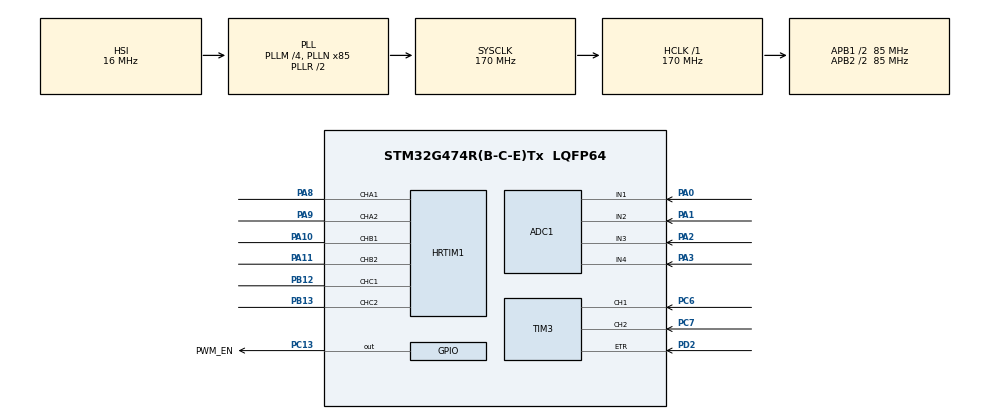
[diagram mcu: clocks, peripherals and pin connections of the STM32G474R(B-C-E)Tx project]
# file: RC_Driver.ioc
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ADC1.Channel-0\#ChannelRegularConversion=ADC_CHANNEL_1
ADC1.EnableInjectedConversion=ENABLE
ADC1.ExternalTrigInjecConv=ADC_EXTERNALTRIGINJEC_HRTIM_TRG2
ADC1.InjNumberOfConversion=4
ADC1.InjectedChannel-1\#ChannelInjectedConversion=ADC_CHANNEL_1
ADC1.InjectedChannel-2\#ChannelInjectedConversion=ADC_CHANNEL_2
ADC1.InjectedChannel-3\#ChannelInjectedConversion=ADC_CHANNEL_3
ADC1.InjectedChannel-4\#ChannelInjectedConversion=ADC_CHANNEL_4
ADC1.InjectedOffsetNumber-1\#ChannelInjectedConversion=ADC_OFFSET_NONE
ADC1.InjectedOffsetNumber-2\#ChannelInjectedConversion=ADC_OFFSET_NONE
ADC1.InjectedOffsetNumber-3\#ChannelInjectedConversion=ADC_OFFSET_NONE
ADC1.InjectedOffsetNumber-4\#ChannelInjectedConversion=ADC_OFFSET_NONE
ADC1.InjectedRank-1\#ChannelInjectedConversion=1
ADC1.InjectedRank-2\#ChannelInjectedConversion=2
ADC1.InjectedRank-3\#ChannelInjectedConversion=3
ADC1.InjectedRank-4\#ChannelInjectedConversion=4
ADC1.InjectedSamplingTime-1\#ChannelInjectedConversion=ADC_SAMPLETIME_2CYCLES_5
ADC1.InjectedSamplingTime-2\#ChannelInjectedConversion=ADC_SAMPLETIME_2CYCLES_5
ADC1.InjectedSamplingTime-3\#ChannelInjectedConversion=ADC_SAMPLETIME_2CYCLES_5
ADC1.InjectedSamplingTime-4\#ChannelInjectedConversion=ADC_SAMPLETIME_47CYCLES_5
ADC1.NbrOfConversion=1
ADC1.NbrOfConversionFlag=1
ADC1.OffsetNumber-0\#ChannelRegularConversion=ADC_OFFSET_NONE
ADC1.Rank-0\#ChannelRegularConversion=1
ADC1.Rank1_Channel=ADC_CHANNEL_1
ADC1.Rank2_Channel=ADC_CHANNEL_2
ADC1.Rank3_Channel=ADC_CHANNEL_3
ADC1.Rank4_Channel=ADC_CHANNEL_4
ADC1.SamplingTime-0\#ChannelRegularConversion=ADC_SAMPLETIME_2CYCLES_5
ADC1.master=1
HRTIM1.ADCTrigger2_Source1=HRTIM_ADCTRIGGEREVENT24_TIMERA_PERIOD
HRTIM1.ADCTrigger_Id1=__NULL
HRTIM1.ADCTrigger_Id2=HRTIM_ADCTRIGGER_2
HRTIM1.Adrom_TA=HRTIM_TIM_ADROM_BOTH
HRTIM1.CompareUnit1-MasterTimer=__NULL
HRTIM1.CompareUnit1-Output_TA1TA2=HRTIM_COMPAREUNIT_1
HRTIM1.CompareUnit1-Output_TB1TB2=HRTIM_COMPAREUNIT_1
HRTIM1.CompareUnit1-Output_TC1TC2=HRTIM_COMPAREUNIT_1
HRTIM1.CompareValue1-Output_TA1TA2=0
HRTIM1.CompareValue1-Output_TB1TB2=0
HRTIM1.CompareValue1-Output_TC1TC2=0
HRTIM1.DeadTimeInsertion-Output_TA1TA2=HRTIM_TIMDEADTIMEINSERTION_ENABLED
HRTIM1.DeadTimeInsertion-Output_TB1TB2=HRTIM_TIMDEADTIMEINSERTION_ENABLED
HRTIM1.DeadTimeInsertion-Output_TC1TC2=HRTIM_TIMDEADTIMEINSERTION_ENABLED
HRTIM1.FallingValue-Output_TA1TA2=35
HRTIM1.FallingValue-Output_TB1TB2=35
HRTIM1.FallingValue-Output_TC1TC2=35
HRTIM1.FaultEnable_Source1-Output_TA1TA2=HRTIM_TIMFAULTENABLE_FAULT3
HRTIM1.FaultEnable_Source1-Output_TB1TB2=HRTIM_TIMFAULTENABLE_FAULT3
HRTIM1.FaultEnable_Source1-Output_TC1TC2=HRTIM_TIMFAULTENABLE_FAULT3
HRTIM1.FaultLevel1-Output_TA1TA2=HRTIM_OUTPUTFAULTLEVEL_INACTIVE
HRTIM1.FaultLevel1-Output_TB1TB2=HRTIM_OUTPUTFAULTLEVEL_INACTIVE
HRTIM1.FaultLevel1-Output_TC1TC2=HRTIM_OUTPUTFAULTLEVEL_INACTIVE
HRTIM1.FaultLevel2-Output_TA1TA2=HRTIM_OUTPUTFAULTLEVEL_INACTIVE
HRTIM1.FaultLevel2-Output_TB1TB2=HRTIM_OUTPUTFAULTLEVEL_INACTIVE
HRTIM1.FaultLevel2-Output_TC1TC2=HRTIM_OUTPUTFAULTLEVEL_INACTIVE
HRTIM1.FaultLock-Output_TA1TA2=HRTIM_TIMFAULTLOCK_READWRITE
HRTIM1.Fault_Line1=__NULL
HRTIM1.Fault_Line3=HRTIM_FAULT_3
HRTIM1.Filter_FaultLine3=HRTIM_FAULTFILTER_6
HRTIM1.HRTIMInterruptResquests1=HRTIM_IT_NONE
HRTIM1.NumberADCTriggerSource2=1
HRTIM1.NumberFaultEnable-Output_TA1TA2=1
HRTIM1.NumberFaultEnable-Output_TB1TB2=1
HRTIM1.NumberFaultEnable-Output_TC1TC2=1
HRTIM1.NumberResetSource1-Output_TA1TA2=1
HRTIM1.NumberResetSource1-Output_TB1TB2=1
HRTIM1.NumberResetSource1-Output_TC1TC2=1
HRTIM1.NumberResetSource2_TA=0
HRTIM1.NumberResetSource2_TB=0
HRTIM1.NumberResetSource2_TC=0
HRTIM1.NumberSetSource1-Output_TA1TA2=1
HRTIM1.NumberSetSource1-Output_TB1TB2=1
HRTIM1.NumberSetSource1-Output_TC1TC2=1
HRTIM1.NumberSetSource2_TA=0
HRTIM1.NumberSetSource2_TB=0
HRTIM1.NumberSetSource2_TC=0
HRTIM1.Periode_MASTER=8500
HRTIM1.Periode_TA=4250
HRTIM1.Periode_TB=4250
HRTIM1.Periode_TC=4250
HRTIM1.Polarity2-Output_TA1TA2=HRTIM_OUTPUTPOLARITY_HIGH
HRTIM1.Polarity_FaultLine3=HRTIM_FAULTPOLARITY_LOW
HRTIM1.PreloadEnable-Output_TA1TA2=HRTIM_PRELOAD_ENABLED
HRTIM1.PreloadEnable-Output_TB1TB2=HRTIM_PRELOAD_ENABLED
HRTIM1.PreloadEnable-Output_TC1TC2=HRTIM_PRELOAD_ENABLED
HRTIM1.PrescalerDead-Output_TA1TA2=HRTIM_TIMDEADTIME_PRESCALERRATIO_DIV1
HRTIM1.PrescalerDead-Output_TB1TB2=HRTIM_TIMDEADTIME_PRESCALERRATIO_DIV1
HRTIM1.PrescalerDead-Output_TC1TC2=HRTIM_TIMDEADTIME_PRESCALERRATIO_DIV1
HRTIM1.PrescalerRatio_MASTER=HRTIM_PRESCALERRATIO_DIV1
HRTIM1.PrescalerRatio_TA=HRTIM_PRESCALERRATIO_DIV1
HRTIM1.PrescalerRatio_TB=HRTIM_PRESCALERRATIO_DIV1
HRTIM1.PrescalerRatio_TC=HRTIM_PRESCALERRATIO_DIV1
HRTIM1.RepetitionCounter-MasterTimer=0x01
HRTIM1.RepetitionCounter-Output_TA1TA2=0x01
HRTIM1.RepetitionCounter-Output_TB1TB2=0x01
HRTIM1.RepetitionCounter-Output_TC1TC2=0x1
HRTIM1.ResetOutput1_Source1-Output_TA1TA2=HRTIM_OUTPUTRESET_TIMCMP1
HRTIM1.ResetOutput1_Source1-Output_TB1TB2=HRTIM_OUTPUTRESET_TIMCMP1
HRTIM1.ResetOutput1_Source1-Output_TC1TC2=HRTIM_OUTPUTRESET_TIMCMP1
HRTIM1.RisingValue-Output_TA1TA2=35
HRTIM1.RisingValue-Output_TB1TB2=35
HRTIM1.RisingValue-Output_TC1TC2=35
HRTIM1.SetOutput1_Source1-Output_TA1TA2=HRTIM_OUTPUTSET_TIMPER
HRTIM1.SetOutput1_Source1-Output_TB1TB2=HRTIM_OUTPUTSET_TIMPER
HRTIM1.SetOutput1_Source1-Output_TC1TC2=HRTIM_OUTPUTSET_TIMPER
HRTIM1.UpDownMode-Output_TA1TA2=HRTIM_TIMERUPDOWNMODE_UPDOWN
HRTIM1.UpDownMode-Output_TB1TB2=HRTIM_TIMERUPDOWNMODE_UPDOWN
HRTIM1.UpDownMode-Output_TC1TC2=HRTIM_TIMERUPDOWNMODE_UPDOWN
Mcu.Family=STM32G4
Mcu.Name=STM32G474R(B-C-E)Tx
Mcu.Package=LQFP64
NVIC.ADC1_2_IRQn=true\:0\:0\:false\:false\:true\:true\:true\:true
NVIC.HRTIM1_FLT_IRQn=true\:0\:0\:false\:false\:true\:true\:true\:true
NVIC.PriorityGroup=NVIC_PRIORITYGROUP_4
NVIC.TIM2_IRQn=true\:0\:0\:false\:false\:true\:true\:true\:true
PA0.Mode=IN1-Single-Ended
PA0.Signal=ADC1_IN1
PA1.Mode=IN2-Single-Ended
PA1.Signal=ADC1_IN2
PA10.Mode=Output_TB1TB2
PA10.Signal=HRTIM1_CHB1
PA11.Mode=Output_TB1TB2
PA11.Signal=HRTIM1_CHB2
PA13.Mode=Serial_Wire
PA13.Signal=SYS_JTMS-SWDIO
PA14.Mode=Serial_Wire
PA14.Signal=SYS_JTCK-SWCLK
PA2.Mode=IN3-Single-Ended
PA2.Signal=ADC1_IN3
PA3.Mode=IN4-Single-Ended
PA3.Signal=ADC1_IN4
PA8.Mode=Output_TA1TA2
PA8.Signal=HRTIM1_CHA1
PA9.Mode=Output_TA1TA2
PA9.Signal=HRTIM1_CHA2
PB12.Mode=Output_TC1TC2
PB12.Signal=HRTIM1_CHC1
PB13.Mode=Output_TC1TC2
PB13.Signal=HRTIM1_CHC2
PC13.GPIO_Label=PWM_EN
PC13.Signal=GPIO_Output
PC6.Signal=S_TIM3_CH1
PC7.Signal=S_TIM3_CH2
PD2.Signal=S_TIM3_ETR
ProjectManager.HeapSize=0x200
ProjectManager.StackSize=0x400
ProjectManager.TargetToolchain=STM32CubeIDE
RCC.ADC12Freq_Value=170000000
RCC.ADC345Freq_Value=170000000
RCC.AHBFreq_Value=170000000
RCC.APB1CLKDivider=RCC_HCLK_DIV2
RCC.APB1Freq_Value=85000000
RCC.APB1TimFreq_Value=170000000
RCC.APB2CLKDivider=RCC_HCLK_DIV2
RCC.APB2Freq_Value=85000000
RCC.APB2TimFreq_Value=170000000
RCC.CortexFreq_Value=170000000
RCC.EXTERNAL_CLOCK_VALUE=12288000
RCC.HCLKFreq_Value=170000000
RCC.HSE_VALUE=8000000
RCC.HSI48_VALUE=48000000
RCC.HSI_VALUE=16000000
RCC.LSE_VALUE=32768
RCC.PLLM=RCC_PLLM_DIV4
RCC.PLLN=85
RCC.SYSCLKFreq_VALUE=170000000
RCC.SYSCLKSource=RCC_SYSCLKSOURCE_PLLCLK
RCC.USBFreq_Value=170000000
RCC.VCOOutputFreq_Value=340000000
SH.S_TIM3_CH1.0=TIM3_CH1,Encoder_Interface_w_index
SH.S_TIM3_CH2.0=TIM3_CH2,Encoder_Interface_w_index
SH.S_TIM3_ETR.0=TIM3_ETR,Encoder_Interface_w_index
TIM2.Channel-Output\ Compare2\ No\ Output=TIM_CHANNEL_2
TIM2.PeriodNoDither=17000-1
TIM2.PulseNoDither_2=2100
TIM2.TIM_MasterOutputTrigger=TIM_TRGO_OC1
TIM2.TIM_MasterSlaveMode=TIM_MASTERSLAVEMODE_ENABLE
VP_HRTIM1_VS_hrtimMasterTimerNoOutput.Mode=MasterTimer
VP_SYS_VS_DBSignals.Mode=DisableDeadBatterySignals
VP_TIM2_VS_ClockSourceINT.Mode=Internal
VP_TIM2_VS_no_output2.Mode=Output Compare2 No Output
board=custom

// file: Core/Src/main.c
/* USER CODE BEGIN Header */
/**
  ******************************************************************************
  * @file           : main.c
  * @brief          : Main program body
  ******************************************************************************
  * @attention
  *
  * Copyright (c) 2026 STMicroelectronics.
  * All rights reserved.
  *
  * This software is licensed under terms that can be found in the LICENSE file
  * in the root directory of this software component.
  * If no LICENSE file comes with this software, it is provided AS-IS.
  *
  ******************************************************************************
  */
/* USER CODE END Header */
#include "main.h"
#include "adc.h"
#include "hrtim.h"
#include "tim.h"
#include "gpio.h"

/* USER CODE BEGIN PV */
float dutyCycle = 0.0f;
/* USER CODE END PV */

void SystemClock_Config(void);

int main(void)
{

  /* MCU Configuration--------------------------------------------------------*/

  /* Reset of all peripherals, Initializes the Flash interface and the Systick. */
  HAL_Init();

  /* Configure the system clock */
  SystemClock_Config();

  /* Initialize all configured peripherals */
  MX_GPIO_Init();
  MX_HRTIM1_Init();
  MX_ADC1_Init();
  MX_TIM3_Init();
  MX_TIM2_Init();
  /* USER CODE BEGIN 2 */

  //  InitParameter(&INV,
  //  			//		SPM
  //  			0.2034f,		// Rs
  //  			2.941e-3,	// Ld
  //  			2.941e-3,	// Lq
  //  			0.07796f,	// Lamf
  //  			4.f,		// PP
  //  			0.748e-3,	// Jm
  //  			1.e-4,	// Bm
  //  			1.f,		// Idsr_align
  //  			4.5f,		// Is_rated  // 12.445
  //  			3.0f,		// Is_limit
  //  			3000.f,	// Wrpm_rated
  //  			0.776f	// Te_rated
  //  );

    //InitParameter(&INV, 5.87e-3, 0.61e-6, 0.61e-6, 728e-6, 4.f, 1e-6, 1e-6, 2.f, 10.f, 20.f, 35000.f, 1e-2); // Velineon 3500
    InitParameter(&INV, 19e-3, 3.2e-6, 3.2e-6, 2e-3, 1.f, 1e-6, 1e-6, 2.f, 50.f, 50.f, 10000.f, 3); // XERUN 13.5T
  //  InitParameter(&INV, 7.85e-3, 0.35e-6, 0.35e-6, 0.711e-3, 4.f, 1e-6, 1e-6, 2.f, 40.f, 40.f, 10000.f, 3); // CASTLE 13.5T

    InitSpeedController(&INV, PI2*25.f, 0.707f);		//PI2*2.	0.707
  //  InitFluxWeakeningController(&INV, 0.0001f, 1.f);
  //  InitTorqueController(&INV);
    InitCurrentController(&INV, PI2*1000.f);	//PI2*200.

    Init_Spd_PLL(&INV, PI2*20.f);
    initExtended_Sensorless_Synchronous_Frame(&EXT_1, PI2*200.f, INV.Rs, INV.Ld, INV.Lq);

    //HAL_ADCEx_Calibration_Start(&hadc1, ADC_SINGLE_ENDED); // Idc

    HAL_ADC_Start_IT(&hadc1);
    HAL_ADCEx_InjectedStart_IT(&hadc1);
    //HAL_ADC_Start_DMA(&hadc1, adc1Val, 4);
  //  HAL_TIM_Base_Start_IT(&htim2);
    HAL_TIM_OC_Start_IT(&htim2, TIM_CHANNEL_2);

    HAL_TIMEx_HallSensor_Start_IT(&htim3);

    FLAG.READY = 1;
    FLAG.FAULT = 0;       // 에러 상태 해제
    FLAG.DUTY_TEST = 1;   // DUTY_TEST 모드 진입 (50% 듀티 출력)

    HAL_TIM_Base_Start_IT(&htim2); // TIM2 10kHz 제어 루프 시작 (이 안에서 Control() 호출)

  /* USER CODE END 2 */

  /* Infinite loop */
  while (1)
  {

  }
}

void SystemClock_Config(void)
{
  RCC_OscInitTypeDef RCC_OscInitStruct = {0};
  RCC_ClkInitTypeDef RCC_ClkInitStruct = {0};

  /** Configure the main internal regulator output voltage
  */
  HAL_PWREx_ControlVoltageScaling(PWR_REGULATOR_VOLTAGE_SCALE1_BOOST);

  /** Initializes the RCC Oscillators according to the specified parameters
  * in the RCC_OscInitTypeDef structure.
  */
  RCC_OscInitStruct.OscillatorType = RCC_OSCILLATORTYPE_HSI;
  RCC_OscInitStruct.HSIState = RCC_HSI_ON;
  RCC_OscInitStruct.HSICalibrationValue = RCC_HSICALIBRATION_DEFAULT;
  RCC_OscInitStruct.PLL.PLLState = RCC_PLL_ON;
  RCC_OscInitStruct.PLL.PLLSource = RCC_PLLSOURCE_HSI;
  RCC_OscInitStruct.PLL.PLLM = RCC_PLLM_DIV4;
  RCC_OscInitStruct.PLL.PLLN = 85;
  RCC_OscInitStruct.PLL.PLLP = RCC_PLLP_DIV2;
  RCC_OscInitStruct.PLL.PLLQ = RCC_PLLQ_DIV2;
  RCC_OscInitStruct.PLL.PLLR = RCC_PLLR_DIV2;
  if (HAL_RCC_OscConfig(&RCC_OscInitStruct) != HAL_OK)
  {
    Error_Handler();
  }

  /** Initializes the CPU, AHB and APB buses clocks
  */
  RCC_ClkInitStruct.ClockType = RCC_CLOCKTYPE_HCLK|RCC_CLOCKTYPE_SYSCLK
                              |RCC_CLOCKTYPE_PCLK1|RCC_CLOCKTYPE_PCLK2;
  RCC_ClkInitStruct.SYSCLKSource = RCC_SYSCLKSOURCE_PLLCLK;
  RCC_ClkInitStruct.AHBCLKDivider = RCC_SYSCLK_DIV1;
  RCC_ClkInitStruct.APB1CLKDivider = RCC_HCLK_DIV2;
  RCC_ClkInitStruct.APB2CLKDivider = RCC_HCLK_DIV2;

  if (HAL_RCC_ClockConfig(&RCC_ClkInitStruct, FLASH_LATENCY_4) != HAL_OK)
  {
    Error_Handler();
  }
}

void Error_Handler(void)
{
  __disable_irq();
  while (1)
  {
  }
}
